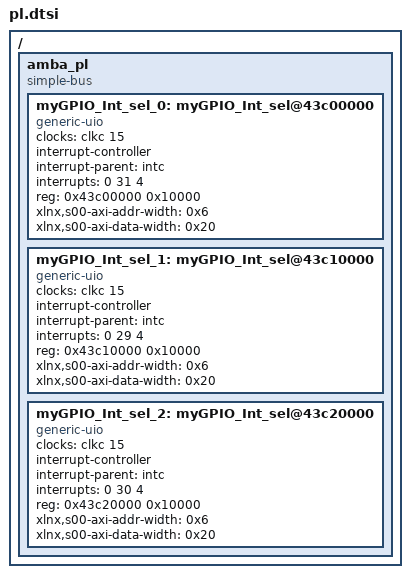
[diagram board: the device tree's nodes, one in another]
/*
 * CAUTION: This file is automatically generated by Xilinx.
 * Version: XSCT 2019.2
 * Today is: Mon Jun 15 17:52:18 2020
 */


/ {
	amba_pl: amba_pl {
		#address-cells = <1>;
		#size-cells = <1>;
		compatible = "simple-bus";
		ranges ;
		myGPIO_Int_sel_0: myGPIO_Int_sel@43c00000 {
			/* This is a place holder node for a custom IP, user may need to update the entries */
			clock-names = "s00_axi_aclk";
			clocks = <&clkc 15>;
			/*compatible = "xlnx,myGPIO-Int-sel-1.0";*/
			/*compatible = "myGPIOK";*/
			compatible = "generic-uio";
			interrupt-controller;
			interrupt-names = "interrupt";
			interrupt-parent = <&intc>;
			interrupts = <0 31 4>;
			reg = <0x43c00000 0x10000>;
			xlnx,s00-axi-addr-width = <0x6>;
			xlnx,s00-axi-data-width = <0x20>;
		};
		myGPIO_Int_sel_1: myGPIO_Int_sel@43c10000 {
			/* This is a place holder node for a custom IP, user may need to update the entries */
			clock-names = "s00_axi_aclk";
			clocks = <&clkc 15>;
			/*compatible = "xlnx,myGPIO-Int-sel-1.0";*/
			/*compatible = "myGPIOK";*/
			compatible = "generic-uio";
			interrupt-controller;
			interrupt-names = "interrupt";
			interrupt-parent = <&intc>;
			interrupts = <0 29 4>;
			reg = <0x43c10000 0x10000>;
			xlnx,s00-axi-addr-width = <0x6>;
			xlnx,s00-axi-data-width = <0x20>;
		};
		myGPIO_Int_sel_2: myGPIO_Int_sel@43c20000 {
			/* This is a place holder node for a custom IP, user may need to update the entries */
			clock-names = "s00_axi_aclk";
			clocks = <&clkc 15>;
			/*compatible = "xlnx,myGPIO-Int-sel-1.0";*/
			/*compatible = "myGPIOK";*/
			compatible = "generic-uio";
			interrupt-controller;
			interrupt-names = "interrupt";
			interrupt-parent = <&intc>;
			interrupts = <0 30 4>;
			reg = <0x43c20000 0x10000>;
			xlnx,s00-axi-addr-width = <0x6>;
			xlnx,s00-axi-data-width = <0x20>;
		};
	};
};
